VERSION ""

NS_ :

BS_:

BU_:

BO_ 2028 Battery: 62 Vector__XXX
 SG_ StateOfChargeBMS m257 : 71|8@0+ (0.5,3) [0|100] "%" Vector__XXX
 SG_ response m98M : 23|16@0+ (1,0) [0|0] "unit" Vector__XXX
 SG_ service M : 15|8@0+ (1,0) [0|0] "" Vector__XXX
 SG_ MinCellVoltage m257 : 239|8@0+ (0.02,0) [2.8|4.2] "V" Vector__XXX
 SG_ MaxCellVoltage m257 : 223|8@0+ (0.02,0) [2.8|4.2] "V" Vector__XXX
 SG_ StateOfChargeDisplay m261 : 287|8@0+ (0.5,3) [0|0] "%" Vector__XXX
 SG_ BatteryTemperature1 m257 : 167|8@0- (1,0) [0|0] "degC" Vector__XXX
 SG_ BatteryTemperature2 m257 : 175|8@0- (1,0) [0|0] "degC" Vector__XXX
 SG_ BatteryTemperature3 m257 : 183|8@0- (1,0) [0|0] "degC" Vector__XXX
 SG_ BatteryTemperature4 m257 : 191|8@0- (1,0) [0|0] "degC" Vector__XXX
 SG_ BatteryMinTemperature m257 : 159|8@0- (1,0) [0|0] "degC" Vector__XXX
 SG_ BatteryMaxTemperature m257 : 151|8@0- (1,0) [0|0] "degC" Vector__XXX
 SG_ BatteryHeaterTemperature1 m261 : 223|8@0- (1,0) [0|0] "degC" Vector__XXX
 SG_ BatteryVoltageAuxillary m257 : 271|8@0+ (0.1,0) [11|14.6] "V" Vector__XXX
 SG_ BatteryTemperature5 m257 : 199|8@0- (1,0) [0|0.5] "V" Vector__XXX
 SG_ BatteryFanFeedback m257 : 263|8@0+ (1,0) [0|120] "Hz" Vector__XXX
 SG_ BatteryFanStatus m257 : 255|8@0+ (1,0) [0|9] "" Vector__XXX
 SG_ NormalChargePort m257 : 109|1@0+ (1,0) [0|0] "" Vector__XXX
 SG_ RapidChargePort m257 : 110|1@0+ (1,0) [0|0] "" Vector__XXX
 SG_ OperatingTime m257 : 383|32@0+ (0.00027777777,0) [0|1000000] "hours" Vector__XXX
 SG_ MinDeterioration m261 : 255|16@0+ (0.1,0) [0|100] "%" Vector__XXX
 SG_ MinDeteriorationCellNo m261 : 279|8@0+ (1,0) [0|98] "" Vector__XXX
 SG_ MinCellVoltageCellNo m257 : 247|8@0+ (1,0) [0|0] "" Vector__XXX
 SG_ MaxCellVoltageCellNo m257 : 231|8@0+ (1,0) [0|0] "" Vector__XXX
 SG_ Charging m257 : 111|1@0+ (1,0) [0|0] "" Vector__XXX
 SG_ CCC_CumulativeChargeCurrent m257 : 263|32@0+ (0.1,0) [0|1000000] "Ah" Vector__XXX
 SG_ CDC_CumulativeDischargeCurrent m257 : 287|32@0+ (0.1,0) [0|1000000] "Ah" Vector__XXX
 SG_ CEC_CumulativeEnergyCharged m257 : 319|32@0+ (0.1,0) [0|1000000] "kWh" Vector__XXX
 SG_ CED_CumulativeEnergyDischarged m257 : 351|32@0+ (0.1,0) [0|1000000] "kWh" Vector__XXX
 SG_ BMSMainRelay m257 : 104|1@0+ (1,0) [0|0] "" Vector__XXX
 SG_ BMSIgnition m257 : 434|1@0+ (1,0) [0|0] "" Vector__XXX
 SG_ BatteryDCVoltage m257 : 135|16@0+ (0.1,0) [0|0] "V" Vector__XXX
 SG_ BatteryCurrent m257 : 119|16@0- (0.1,0) [-230|230] "A" Vector__XXX
 SG_ BatteryAvailableChargePower m261 : 167|16@0+ (0.01,0) [0|270] "kW" Vector__XXX
 SG_ BatteryAvailableDischargePower m261 : 183|16@0+ (0.01,0) [0|270] "kW" Vector__XXX
 SG_ CellVoltage01 m258 : 71|8@0+ (0.02,0) [2.8|4.2] "V" Vector__XXX
 SG_ CellVoltage02 m258 : 79|8@0+ (0.02,0) [2.8|4.2] "V" Vector__XXX
 SG_ CellVoltage03 m258 : 87|8@0+ (0.02,0) [2.8|4.2] "V" Vector__XXX
 SG_ CellVoltage04 m258 : 95|8@0+ (0.02,0) [2.8|4.2] "V" Vector__XXX
 SG_ CellVoltage05 m258 : 103|8@0+ (0.02,0) [2.8|4.2] "V" Vector__XXX
 SG_ CellVoltage06 m258 : 111|8@0+ (0.02,0) [2.8|4.2] "V" Vector__XXX
 SG_ CellVoltage07 m258 : 119|8@0+ (0.02,0) [2.8|4.2] "V" Vector__XXX
 SG_ CellVoltage08 m258 : 127|8@0+ (0.02,0) [2.8|4.2] "V" Vector__XXX
 SG_ CellVoltage09 m258 : 135|8@0+ (0.02,0) [2.8|4.2] "V" Vector__XXX
 SG_ CellVoltage10 m258 : 143|8@0+ (0.02,0) [2.8|4.2] "V" Vector__XXX
 SG_ CellVoltage11 m258 : 151|8@0+ (0.02,0) [2.8|4.2] "V" Vector__XXX
 SG_ CellVoltage12 m258 : 159|8@0+ (0.02,0) [2.8|4.2] "V" Vector__XXX
 SG_ CellVoltage13 m258 : 167|8@0+ (0.02,0) [2.8|4.2] "V" Vector__XXX
 SG_ CellVoltage14 m258 : 175|8@0+ (0.02,0) [2.8|4.2] "V" Vector__XXX
 SG_ CellVoltage15 m258 : 183|8@0+ (0.02,0) [2.8|4.2] "V" Vector__XXX
 SG_ CellVoltage16 m258 : 191|8@0+ (0.02,0) [2.8|4.2] "V" Vector__XXX
 SG_ CellVoltage17 m258 : 199|8@0+ (0.02,0) [2.8|4.2] "V" Vector__XXX
 SG_ CellVoltage18 m258 : 207|8@0+ (0.02,0) [2.8|4.2] "V" Vector__XXX
 SG_ CellVoltage19 m258 : 215|8@0+ (0.02,0) [2.8|4.2] "V" Vector__XXX
 SG_ CellVoltage20 m258 : 223|8@0+ (0.02,0) [2.8|4.2] "V" Vector__XXX
 SG_ StateOfHealth m261 : 239|16@0+ (0.1,0) [0|100] "%" Vector__XXX

BO_ 1979 Temperature: 54 Vector__XXX
 SG_ IndoorTemperature m256 : 79|8@0+ (0.5,-40) [-50|50] "degC" Vector__XXX
 SG_ response m98M : 23|16@0+ (1,0) [0|0] "unit" Vector__XXX
 SG_ service M : 15|8@0+ (1,0) [0|0] "" Vector__XXX
 SG_ OutdoorTemperature m256 : 87|8@0+ (0.5,-40) [-50|50] "degC" Vector__XXX
 SG_ VehicleSpeed m256 : 271|8@0+ (1,0) [0|200] "kmh" Vector__XXX

BO_ 1960 Tire: 64 Vector__XXX
 SG_ response m98M : 23|16@0+ (1,0) [0|0] "" Vector__XXX
 SG_ service M : 15|8@0+ (1,0) [0|0] "" Vector__XXX
 SG_ TirePressureFrontLeft m49163 : 71|8@0+ (0.2,0) [0|120] "psi" Vector__XXX
 SG_ TirePressureFrontRight m49163 : 111|8@0+ (0.2,0) [0|120] "psi" Vector__XXX
 SG_ TirePressureBackLeft m49163 : 151|8@0+ (0.2,0) [0|120] "psi" Vector__XXX
 SG_ TirePressureBackRight m49163 : 191|8@0+ (0.2,0) [0|120] "psi" Vector__XXX
 SG_ TireTemperatureFrontLeft m49163 : 79|8@0+ (1,-50) [-40|65] "degC" Vector__XXX
 SG_ TireTemperatureFrontRight m49163 : 119|8@0+ (1,-50) [-40|65] "degC" Vector__XXX
 SG_ TireTemperatureBackLeft m49163 : 159|8@0+ (1,-50) [-40|65] "degC" Vector__XXX
 SG_ TireTemperatureBackRight m49163 : 199|8@0+ (1,-50) [-40|65] "degC" Vector__XXX

BO_ 3 gnss_pos: 8 Vector__XXX
 SG_ PositionAccuracy : 58|6@1+ (1,0) [0|63] "m" Vector__XXX
 SG_ Latitude : 1|28@1+ (1e-06,-90) [-90|90] "deg" Vector__XXX
 SG_ Longitude : 29|29@1+ (1e-06,-180) [-180|180] "deg" Vector__XXX
 SG_ PositionValid : 0|1@1+ (1,0) [0|1] "" Vector__XXX

BO_ 2 gnss_time: 6 Vector__XXX
 SG_ TimeValid : 0|1@1+ (1,0) [0|1] "" Vector__XXX
 SG_ TimeConfirmed : 1|1@1+ (1,0) [0|1] "" Vector__XXX
 SG_ Epoch : 8|40@1+ (0.001,1577840400) [1577840400|2677352027] "sec" Vector__XXX

BO_ 5 gnss_attitude: 8 Vector__XXX
 SG_ AttitudeValid : 0|1@1+ (1,0) [0|1] "" Vector__XXX
 SG_ Roll : 1|12@1+ (0.1,-180) [-180|180] "deg" Vector__XXX
 SG_ Pitch : 22|12@1+ (0.1,-90) [-90|90] "deg" Vector__XXX
 SG_ Heading : 43|12@1+ (0.1,0) [0|360] "deg" Vector__XXX
 SG_ RollAccuracy : 13|9@1+ (0.1,0) [0|50] "deg" Vector__XXX
 SG_ PitchAccuracy : 34|9@1+ (0.1,0) [0|50] "deg" Vector__XXX
 SG_ HeadingAccuracy : 55|9@1+ (0.1,0) [0|50] "deg" Vector__XXX

BO_ 6 gnss_odo: 8 Vector__XXX
 SG_ DistanceTrip : 1|22@1+ (1,0) [0|4194303] "m" Vector__XXX
 SG_ DistanceAccuracy : 23|19@1+ (1,0) [0|524287] "m" Vector__XXX
 SG_ DistanceValid : 0|1@1+ (1,0) [0|1] "" Vector__XXX
 SG_ DistanceTotal : 42|22@1+ (1,0) [0|4194303] "km" Vector__XXX

BO_ 1 gnss_status: 1 Vector__XXX
 SG_ FixType : 0|3@1+ (1,0) [0|5] "" Vector__XXX
 SG_ Satellites : 3|5@1+ (1,0) [0|31] "" Vector__XXX

BO_ 4 gnss_altitude: 4 Vector__XXX
 SG_ AltitudeValid : 0|1@1+ (1,0) [0|1] "" Vector__XXX
 SG_ Altitude : 1|18@1+ (0.1,-6000) [-6000|20000] "m" Vector__XXX
 SG_ AltitudeAccuracy : 19|13@1+ (1,0) [0|8000] "m" Vector__XXX

BO_ 8 gnss_geofence: 2 Vector__XXX
 SG_ FenceValid : 0|1@1+ (1,0) [0|1] "" Vector__XXX
 SG_ FenceCombined : 1|2@1+ (1,0) [0|1] "" Vector__XXX
 SG_ Fence1 : 8|2@1+ (1,0) [0|1] "" Vector__XXX
 SG_ Fence2 : 10|2@1+ (1,0) [0|1] "" Vector__XXX
 SG_ Fence3 : 12|2@1+ (1,0) [0|1] "" Vector__XXX
 SG_ Fence4 : 14|2@1+ (1,0) [0|1] "" Vector__XXX

BO_ 7 gnss_speed: 5 Vector__XXX
 SG_ Speed : 1|20@1+ (0.001,0) [0|1048.575] "m/s" Vector__XXX
 SG_ SpeedAccuracy : 21|19@1+ (0.001,0) [0|524.287] "m/s" Vector__XXX
 SG_ SpeedValid : 0|1@1+ (1,0) [0|1] "" Vector__XXX

BO_ 9 gnss_imu: 8 Vector__XXX
 SG_ AccelerationX : 1|10@1+ (0.125,-64) [-64|63.875] "m/s^2" Vector__XXX
 SG_ AccelerationY : 11|10@1+ (0.125,-64) [-64|63.875] "m/s^2" Vector__XXX
 SG_ AccelerationZ : 21|10@1+ (0.125,-64) [-64|63.875] "m/s^2" Vector__XXX
 SG_ AngularRateX : 31|11@1+ (0.25,-256) [-256|255.75] "deg/s" Vector__XXX
 SG_ AngularRateY : 42|11@1+ (0.25,-256) [-256|255.75] "deg/s" Vector__XXX
 SG_ AngularRateZ : 53|11@1+ (0.25,-256) [-256|255.75] "deg/s" Vector__XXX
 SG_ ImuValid : 0|1@1+ (1,0) [0|1] "" Vector__XXX

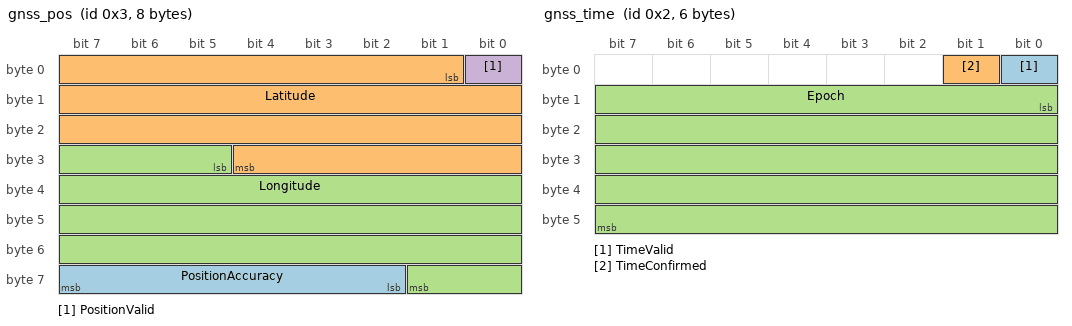
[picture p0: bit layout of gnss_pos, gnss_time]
BO_ 19 gnss_pos: 8 Vector__XXX
 SG_ PositionAccuracy : 58|6@1+ (1,0) [0|63] "m" Vector__XXX
 SG_ Latitude : 1|28@1+ (1E-006,-90) [-90|90] "deg" Vector__XXX
 SG_ Longitude : 29|29@1+ (1E-006,-180) [-180|180] "deg" Vector__XXX
 SG_ PositionValid : 0|1@1+ (1,0) [0|1] "" Vector__XXX

BO_ 18 gnss_time: 6 Vector__XXX
 SG_ TimeValid : 0|1@1+ (1,0) [0|1] "" Vector__XXX
 SG_ TimeConfirmed : 1|1@1+ (1,0) [0|1] "" Vector__XXX
 SG_ Epoch : 8|40@1+ (0.001,1577840400) [1577840400|2677352027] "sec" Vector__XXX

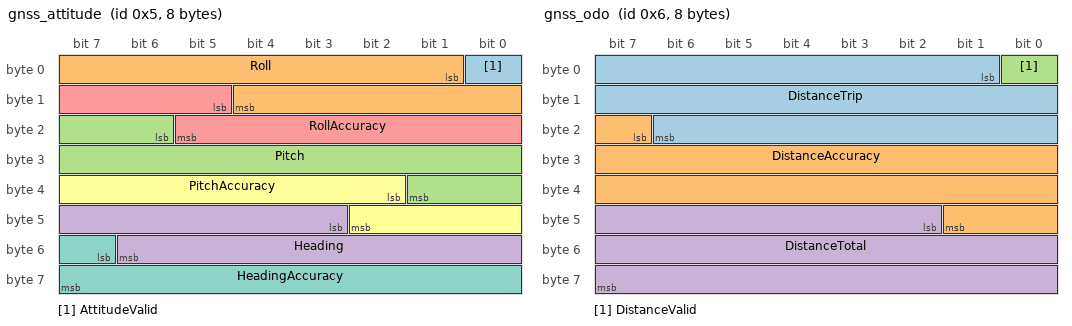
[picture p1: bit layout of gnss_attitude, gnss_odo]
BO_ 21 gnss_attitude: 8 Vector__XXX
 SG_ AttitudeValid : 0|1@1+ (1,0) [0|1] "" Vector__XXX
 SG_ Roll : 1|12@1+ (0.1,-180) [-180|180] "deg" Vector__XXX
 SG_ Pitch : 22|12@1+ (0.1,-90) [-90|90] "deg" Vector__XXX
 SG_ Heading : 43|12@1+ (0.1,0) [0|360] "deg" Vector__XXX
 SG_ RollAccuracy : 13|9@1+ (0.1,0) [0|50] "deg" Vector__XXX
 SG_ PitchAccuracy : 34|9@1+ (0.1,0) [0|50] "deg" Vector__XXX
 SG_ HeadingAccuracy : 55|9@1+ (0.1,0) [0|50] "deg" Vector__XXX

BO_ 22 gnss_odo: 8 Vector__XXX
 SG_ DistanceTrip : 1|22@1+ (1,0) [0|4194303] "m" Vector__XXX
 SG_ DistanceAccuracy : 23|19@1+ (1,0) [0|524287] "m" Vector__XXX
 SG_ DistanceValid : 0|1@1+ (1,0) [0|1] "" Vector__XXX
 SG_ DistanceTotal : 42|22@1+ (1,0) [0|4194303] "km" Vector__XXX

BO_ 17 gnss_status: 1 Vector__XXX
 SG_ FixType : 0|3@1+ (1,0) [0|5] "" Vector__XXX
 SG_ Satellites : 3|5@1+ (1,0) [0|31] "" Vector__XXX

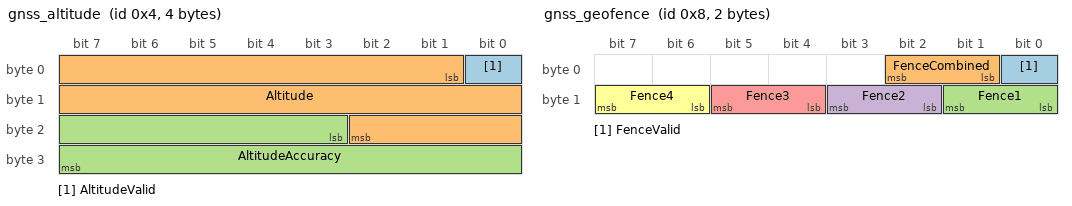
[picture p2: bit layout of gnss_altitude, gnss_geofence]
BO_ 20 gnss_altitude: 4 Vector__XXX
 SG_ AltitudeValid : 0|1@1+ (1,0) [0|1] "" Vector__XXX
 SG_ Altitude : 1|18@1+ (0.1,-6000) [-6000|20000] "m" Vector__XXX
 SG_ AltitudeAccuracy : 19|13@1+ (1,0) [0|8000] "m" Vector__XXX

BO_ 24 gnss_geofence: 2 Vector__XXX
 SG_ FenceValid : 0|1@1+ (1,0) [0|1] "" Vector__XXX
 SG_ FenceCombined : 1|2@1+ (1,0) [0|1] "" Vector__XXX
 SG_ Fence1 : 8|2@1+ (1,0) [0|1] "" Vector__XXX
 SG_ Fence2 : 10|2@1+ (1,0) [0|1] "" Vector__XXX
 SG_ Fence3 : 12|2@1+ (1,0) [0|1] "" Vector__XXX
 SG_ Fence4 : 14|2@1+ (1,0) [0|1] "" Vector__XXX

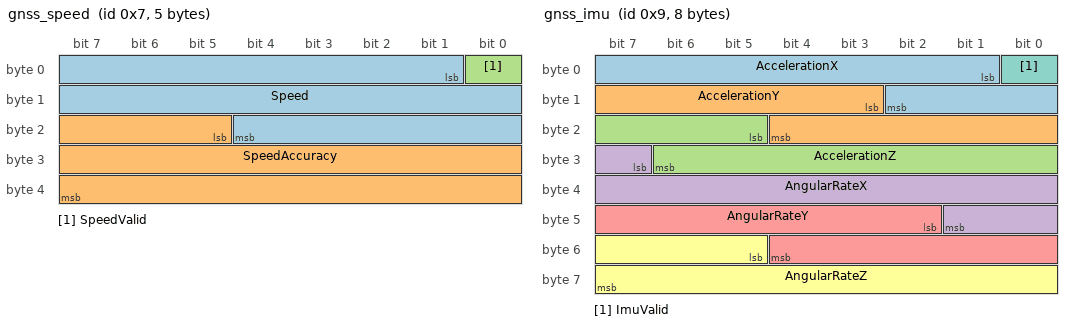
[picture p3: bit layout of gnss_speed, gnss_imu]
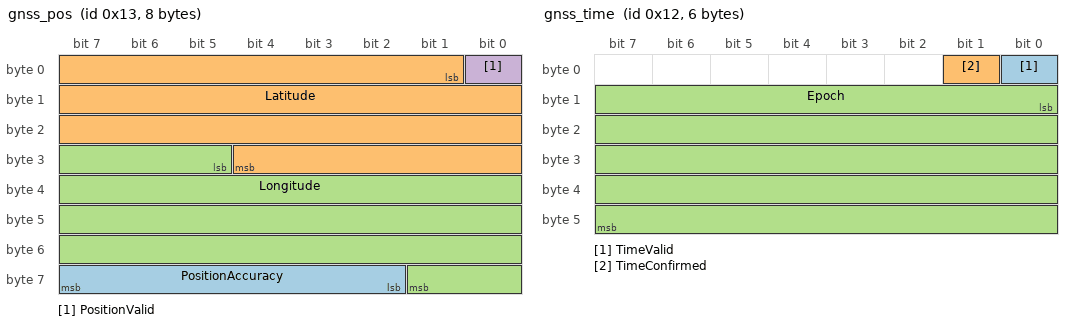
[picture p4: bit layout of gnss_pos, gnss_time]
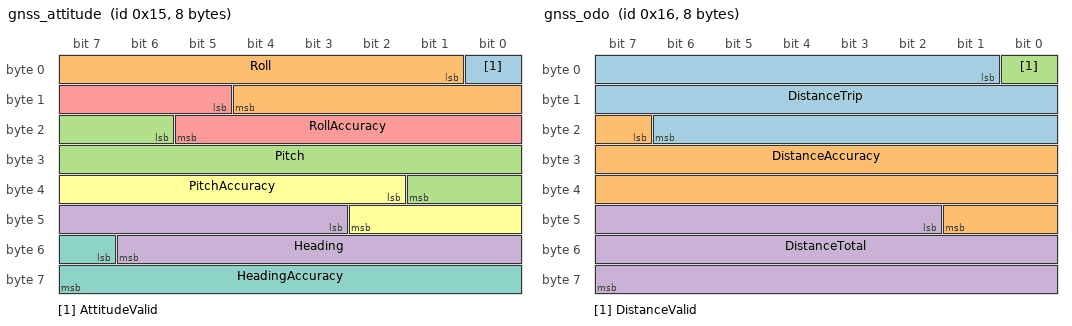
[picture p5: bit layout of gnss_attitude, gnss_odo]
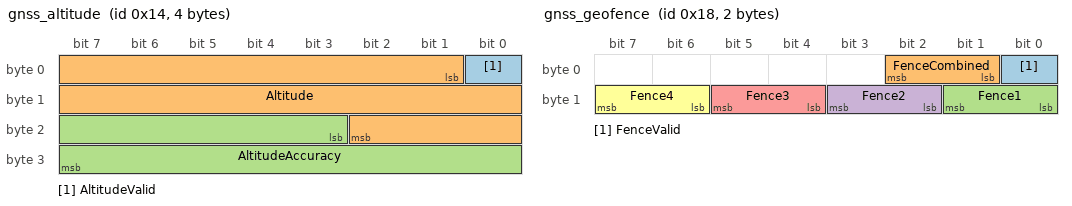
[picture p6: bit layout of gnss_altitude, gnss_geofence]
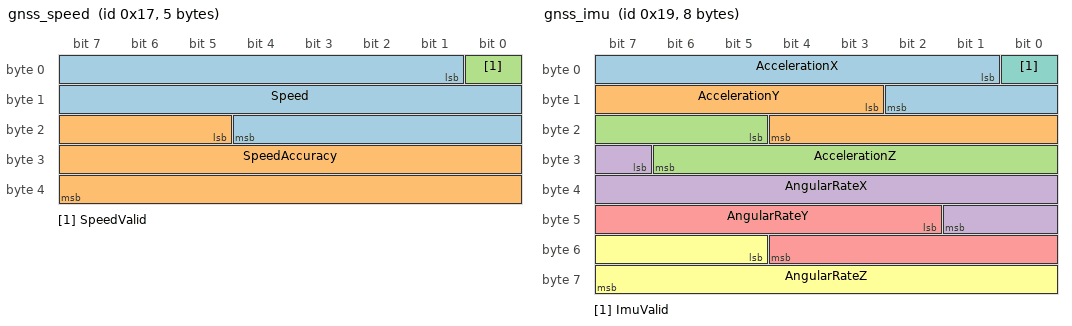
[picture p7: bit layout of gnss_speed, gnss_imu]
BO_ 23 gnss_speed: 5 Vector__XXX
 SG_ Speed : 1|20@1+ (0.001,0) [0|1048.575] "m/s" Vector__XXX
 SG_ SpeedAccuracy : 21|19@1+ (0.001,0) [0|524.287] "m/s" Vector__XXX
 SG_ SpeedValid : 0|1@1+ (1,0) [0|1] "" Vector__XXX

BO_ 25 gnss_imu: 8 Vector__XXX
 SG_ AccelerationX : 1|10@1+ (0.125,-64) [-64|63.875] "m/s^2" Vector__XXX
 SG_ AccelerationY : 11|10@1+ (0.125,-64) [-64|63.875] "m/s^2" Vector__XXX
 SG_ AccelerationZ : 21|10@1+ (0.125,-64) [-64|63.875] "m/s^2" Vector__XXX
 SG_ AngularRateX : 31|11@1+ (0.25,-256) [-256|255.75] "deg/s" Vector__XXX
 SG_ AngularRateY : 42|11@1+ (0.25,-256) [-256|255.75] "deg/s" Vector__XXX
 SG_ AngularRateZ : 53|11@1+ (0.25,-256) [-256|255.75] "deg/s" Vector__XXX
 SG_ ImuValid : 0|1@1+ (1,0) [0|1] "" Vector__XXX

CM_ BO_ 3 "GNSS position";
CM_ SG_ 3 PositionAccuracy "Accuracy of position";
CM_ SG_ 3 Latitude "Latitude";
CM_ SG_ 3 Longitude "Longitude";
CM_ SG_ 3 PositionValid "Position validity";
CM_ BO_ 2 "GNSS time";
CM_ SG_ 2 TimeValid "Time validity";
CM_ SG_ 2 TimeConfirmed "Time confirmed";
CM_ SG_ 2 Epoch "Epoch time";
CM_ BO_ 5 "GNSS attitude";
CM_ SG_ 5 AttitudeValid "Attitude validity";
CM_ SG_ 5 Roll "Vehicle roll";
CM_ SG_ 5 Pitch "Vehicle pitch";
CM_ SG_ 5 Heading "Vehicle heading";
CM_ SG_ 5 RollAccuracy "Vehicle roll accuracy";
CM_ SG_ 5 PitchAccuracy "Vehicle pitch accuracy";
CM_ SG_ 5 HeadingAccuracy "Vehicle heading accuracy";
CM_ BO_ 6 "GNSS odometer";
CM_ SG_ 6 DistanceTrip "Distance traveled since last reset";
CM_ SG_ 6 DistanceAccuracy "Distance accuracy (1-sigma)";
CM_ SG_ 6 DistanceTotal "Distance traveled in total";
CM_ BO_ 1 "GNSS information";
CM_ SG_ 1 FixType "Fix type";
CM_ SG_ 1 Satellites "Number of satellites used";
CM_ BO_ 4 "GNSS altitude";
CM_ SG_ 4 AltitudeValid "Altitude validity";
CM_ SG_ 4 Altitude "Altitude";
CM_ SG_ 4 AltitudeAccuracy "Accuracy of altitude";
CM_ BO_ 8 "GNSS geofence(s)";
CM_ SG_ 8 FenceValid "Geofencing status";
CM_ SG_ 8 FenceCombined "Combined (logical OR) state of all geofences";
CM_ SG_ 8 Fence1 "Geofence 1 state";
CM_ SG_ 8 Fence2 "Geofence 2 state";
CM_ SG_ 8 Fence3 "Geofence 3 state";
CM_ SG_ 8 Fence4 "Geofence 4 state";
CM_ BO_ 7 "GNSS speed";
CM_ SG_ 7 Speed "Speed";
CM_ SG_ 7 SpeedAccuracy "Speed accuracy";
CM_ BO_ 9 "GNSS IMU";
CM_ SG_ 9 AccelerationX "X acceleration with a resolution of 0.125 m/s^2";
CM_ SG_ 9 AccelerationY "Y acceleration with a resolution of 0.125 m/s^2";
CM_ SG_ 9 AccelerationZ "Z acceleration with a resolution of 0.125 m/s^2";
CM_ SG_ 9 AngularRateX "X angular rate with a resolution of 0.25 deg/s";
CM_ SG_ 9 AngularRateY "Y angular rate with a resolution of 0.25 deg/s";
CM_ SG_ 9 AngularRateZ "Z angular rate with a resolution of 0.25 deg/s";
CM_ BO_ 19 "GNSS position";
CM_ SG_ 19 PositionAccuracy "Accuracy of position";
CM_ SG_ 19 Latitude "Latitude";
CM_ SG_ 19 Longitude "Longitude";
CM_ SG_ 19 PositionValid "Position validity";
CM_ BO_ 18 "GNSS time";
CM_ SG_ 18 TimeValid "Time validity";
CM_ SG_ 18 TimeConfirmed "Time confirmed";
CM_ SG_ 18 Epoch "Epoch time";
CM_ BO_ 21 "GNSS attitude";
CM_ SG_ 21 AttitudeValid "Attitude validity";
CM_ SG_ 21 Roll "Vehicle roll";
CM_ SG_ 21 Pitch "Vehicle pitch";
CM_ SG_ 21 Heading "Vehicle heading";
CM_ SG_ 21 RollAccuracy "Vehicle roll accuracy";
CM_ SG_ 21 PitchAccuracy "Vehicle pitch accuracy";
CM_ SG_ 21 HeadingAccuracy "Vehicle heading accuracy";
CM_ BO_ 22 "GNSS odometer";
CM_ SG_ 22 DistanceTrip "Distance traveled since last reset";
CM_ SG_ 22 DistanceAccuracy "Distance accuracy (1-sigma)";
CM_ SG_ 22 DistanceTotal "Distance traveled in total";
CM_ BO_ 17 "GNSS information";
CM_ SG_ 17 FixType "Fix type";
CM_ SG_ 17 Satellites "Number of satellites used";
CM_ BO_ 20 "GNSS altitude";
CM_ SG_ 20 AltitudeValid "Altitude validity";
CM_ SG_ 20 Altitude "Altitude";
CM_ SG_ 20 AltitudeAccuracy "Accuracy of altitude";
CM_ BO_ 24 "GNSS geofence(s)";
CM_ SG_ 24 FenceValid "Geofencing status";
CM_ SG_ 24 FenceCombined "Combined (logical OR) state of all geofences";
CM_ SG_ 24 Fence1 "Geofence 1 state";
CM_ SG_ 24 Fence2 "Geofence 2 state";
CM_ SG_ 24 Fence3 "Geofence 3 state";
CM_ SG_ 24 Fence4 "Geofence 4 state";
CM_ BO_ 23 "GNSS speed";
CM_ SG_ 23 Speed "Speed";
CM_ SG_ 23 SpeedAccuracy "Speed accuracy";
CM_ BO_ 25 "GNSS IMU";
CM_ SG_ 25 AccelerationX "X acceleration with a resolution of 0.125 m/s^2";
CM_ SG_ 25 AccelerationY "Y acceleration with a resolution of 0.125 m/s^2";
CM_ SG_ 25 AccelerationZ "Z acceleration with a resolution of 0.125 m/s^2";
CM_ SG_ 25 AngularRateX "X angular rate with a resolution of 0.25 deg/s";
CM_ SG_ 25 AngularRateY "Y angular rate with a resolution of 0.25 deg/s";
CM_ SG_ 25 AngularRateZ "Z angular rate with a resolution of 0.25 deg/s";
BA_DEF_ BO_  "VFrameFormat" ENUM  "StandardCAN","ExtendedCAN","StandardCAN_FD","ExtendedCAN_FD","J1939PG";
BA_DEF_  "ProtocolType" STRING ;
BA_DEF_DEF_  "VFrameFormat" "";
BA_DEF_DEF_  "ProtocolType" "";
BA_ "VFrameFormat" BO_ 2028 0;
BA_ "VFrameFormat" BO_ 1960 0;
VAL_ 3 PositionValid 0 "Invalid" 1 "Valid" ;
VAL_ 2 TimeValid 0 "Invalid" 1 "Valid" ;
VAL_ 2 TimeConfirmed 0 "Unconfirmed" 1 "Confirmed" ;
VAL_ 5 AttitudeValid 0 "Invalid" 1 "Valid" ;
VAL_ 6 DistanceValid 0 "Invalid" 1 "Valid" ;
VAL_ 1 FixType 0 "No fix" 1 "Dead reckoning only" 2 "2D-fix" 3 "3D-fix" 4 "GNSS + dead reckoning combined" 5 "Time only fix" ;
VAL_ 4 AltitudeValid 0 "Invalid" 1 "Valid" ;
VAL_ 8 FenceValid 0 "Invalid" 1 "Valid" ;
VAL_ 8 FenceCombined 0 "Unknown" 1 "Inside" 2 "Outside" ;
VAL_ 8 Fence1 0 "Unknown" 1 "Inside" 2 "Outside" ;
VAL_ 8 Fence2 0 "Unknown" 1 "Inside" 2 "Outside" ;
VAL_ 8 Fence3 0 "Unknown" 1 "Inside" 2 "Outside" ;
VAL_ 8 Fence4 0 "Unknown" 1 "Inside" 2 "Outside" ;
VAL_ 7 SpeedValid 0 "Invalid" 1 "Valid" ;
VAL_ 9 ImuValid 0 "Invalid" 1 "Valid" ;
VAL_ 19 PositionValid 0 "Invalid" 1 "Valid" ;
VAL_ 18 TimeValid 0 "Invalid" 1 "Valid" ;
VAL_ 18 TimeConfirmed 0 "Unconfirmed" 1 "Confirmed" ;
VAL_ 21 AttitudeValid 0 "Invalid" 1 "Valid" ;
VAL_ 22 DistanceValid 0 "Invalid" 1 "Valid" ;
VAL_ 17 FixType 0 "No fix" 1 "Dead reckoning only" 2 "2D-fix" 3 "3D-fix" 4 "GNSS + dead reckoning combined" 5 "Time only fix" ;
VAL_ 20 AltitudeValid 0 "Invalid" 1 "Valid" ;
VAL_ 24 FenceValid 0 "Invalid" 1 "Valid" ;
VAL_ 24 FenceCombined 0 "Unknown" 1 "Inside" 2 "Outside" ;
VAL_ 24 Fence1 0 "Unknown" 1 "Inside" 2 "Outside" ;
VAL_ 24 Fence2 0 "Unknown" 1 "Inside" 2 "Outside" ;
VAL_ 24 Fence3 0 "Unknown" 1 "Inside" 2 "Outside" ;
VAL_ 24 Fence4 0 "Unknown" 1 "Inside" 2 "Outside" ;
VAL_ 23 SpeedValid 0 "Invalid" 1 "Valid" ;
VAL_ 25 ImuValid 0 "Invalid" 1 "Valid" ;
SG_MUL_VAL_ 2028 StateOfChargeBMS response 257-257;
SG_MUL_VAL_ 2028 response service 98-98;
SG_MUL_VAL_ 2028 MinCellVoltage response 257-257;
SG_MUL_VAL_ 2028 MaxCellVoltage response 257-257;
SG_MUL_VAL_ 2028 StateOfChargeDisplay response 261-261;
SG_MUL_VAL_ 2028 BatteryTemperature1 response 257-257;
SG_MUL_VAL_ 2028 BatteryTemperature2 response 257-257;
SG_MUL_VAL_ 2028 BatteryTemperature3 response 257-257;
SG_MUL_VAL_ 2028 BatteryTemperature4 response 257-257;
SG_MUL_VAL_ 2028 BatteryMinTemperature response 257-257;
SG_MUL_VAL_ 2028 BatteryMaxTemperature response 257-257;
SG_MUL_VAL_ 2028 BatteryHeaterTemperature1 response 261-261;
SG_MUL_VAL_ 2028 BatteryVoltageAuxillary response 257-257;
SG_MUL_VAL_ 2028 BatteryTemperature5 response 257-257;
SG_MUL_VAL_ 2028 BatteryFanFeedback response 257-257;
SG_MUL_VAL_ 2028 BatteryFanStatus response 257-257;
SG_MUL_VAL_ 2028 NormalChargePort response 257-257;
SG_MUL_VAL_ 2028 RapidChargePort response 257-257;
SG_MUL_VAL_ 2028 OperatingTime response 257-257;
SG_MUL_VAL_ 2028 MinDeterioration response 261-261;
SG_MUL_VAL_ 2028 MinDeteriorationCellNo response 261-261;
SG_MUL_VAL_ 2028 MinCellVoltageCellNo response 257-257;
SG_MUL_VAL_ 2028 MaxCellVoltageCellNo response 257-257;
SG_MUL_VAL_ 2028 Charging response 257-257;
SG_MUL_VAL_ 2028 CCC_CumulativeChargeCurrent response 257-257;
SG_MUL_VAL_ 2028 CDC_CumulativeDischargeCurrent response 257-257;
SG_MUL_VAL_ 2028 CEC_CumulativeEnergyCharged response 257-257;
SG_MUL_VAL_ 2028 CED_CumulativeEnergyDischarged response 257-257;
SG_MUL_VAL_ 2028 BMSMainRelay response 257-257;
SG_MUL_VAL_ 2028 BMSIgnition response 257-257;
SG_MUL_VAL_ 2028 BatteryDCVoltage response 257-257;
SG_MUL_VAL_ 2028 BatteryCurrent response 257-257;
SG_MUL_VAL_ 2028 BatteryAvailableChargePower response 261-261;
SG_MUL_VAL_ 2028 BatteryAvailableDischargePower response 261-261;
SG_MUL_VAL_ 2028 CellVoltage01 response 258-258;
SG_MUL_VAL_ 2028 CellVoltage02 response 258-258;
SG_MUL_VAL_ 2028 CellVoltage03 response 258-258;
SG_MUL_VAL_ 2028 CellVoltage04 response 258-258;
SG_MUL_VAL_ 2028 CellVoltage05 response 258-258;
SG_MUL_VAL_ 2028 CellVoltage06 response 258-258;
SG_MUL_VAL_ 2028 CellVoltage07 response 258-258;
SG_MUL_VAL_ 2028 CellVoltage08 response 258-258;
SG_MUL_VAL_ 2028 CellVoltage09 response 258-258;
SG_MUL_VAL_ 2028 CellVoltage10 response 258-258;
SG_MUL_VAL_ 2028 CellVoltage11 response 258-258;
SG_MUL_VAL_ 2028 CellVoltage12 response 258-258;
SG_MUL_VAL_ 2028 CellVoltage13 response 258-258;
SG_MUL_VAL_ 2028 CellVoltage14 response 258-258;
SG_MUL_VAL_ 2028 CellVoltage15 response 258-258;
SG_MUL_VAL_ 2028 CellVoltage16 response 258-258;
SG_MUL_VAL_ 2028 CellVoltage17 response 258-258;
SG_MUL_VAL_ 2028 CellVoltage18 response 258-258;
SG_MUL_VAL_ 2028 CellVoltage19 response 258-258;
SG_MUL_VAL_ 2028 CellVoltage20 response 258-258;
SG_MUL_VAL_ 2028 StateOfHealth response 261-261;
SG_MUL_VAL_ 1979 IndoorTemperature response 256-256;
SG_MUL_VAL_ 1979 response service 98-98;
SG_MUL_VAL_ 1979 OutdoorTemperature response 256-256;
SG_MUL_VAL_ 1979 VehicleSpeed response 256-256;
SG_MUL_VAL_ 1960 response service 98-98;
SG_MUL_VAL_ 1960 TirePressureFrontLeft response 49163-49163;
SG_MUL_VAL_ 1960 TirePressureFrontRight response 49163-49163;
SG_MUL_VAL_ 1960 TirePressureBackLeft response 49163-49163;
SG_MUL_VAL_ 1960 TirePressureBackRight response 49163-49163;
SG_MUL_VAL_ 1960 TireTemperatureFrontLeft response 49163-49163;
SG_MUL_VAL_ 1960 TireTemperatureFrontRight response 49163-49163;
SG_MUL_VAL_ 1960 TireTemperatureBackLeft response 49163-49163;
SG_MUL_VAL_ 1960 TireTemperatureBackRight response 49163-49163;
